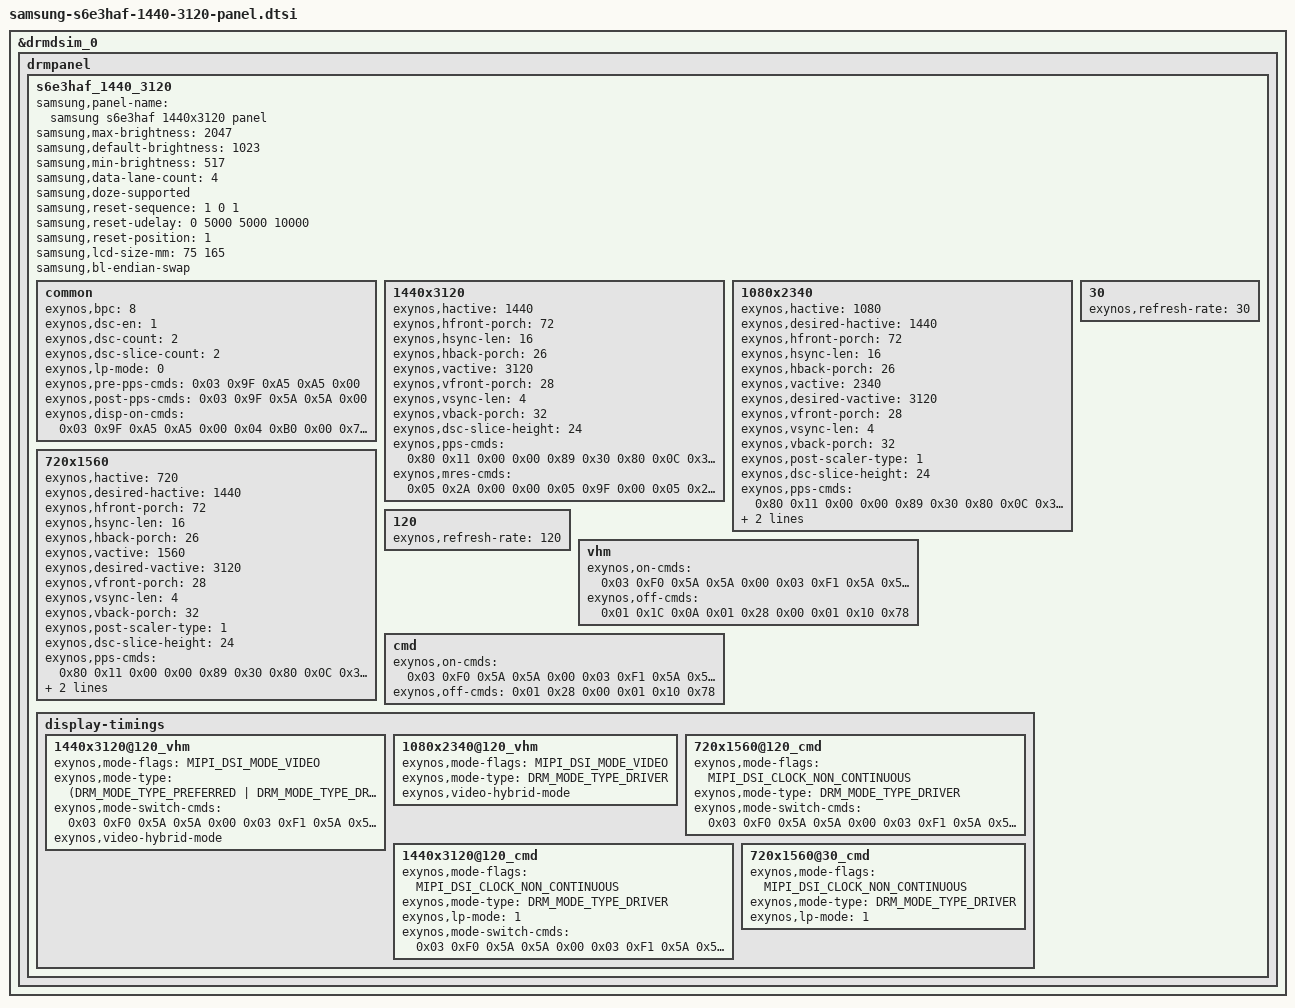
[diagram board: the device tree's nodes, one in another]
#include <dt-bindings/display/exynos-display.h>
#include <dt-bindings/display/exynos-mipi-display.h>

&drmdsim_0 {
	drmpanel {
		s6e3haf_1440_3120: s6e3haf_1440_3120 {
			samsung,panel-name = "samsung s6e3haf 1440x3120 panel";
			samsung,max-brightness = <2047>;
			samsung,default-brightness = <1023>;
			samsung,min-brightness = <517>;
			samsung,data-lane-count = <4>;
			samsung,doze-supported;

			samsung,reset-sequence = <1 0 1>;
			samsung,reset-udelay = <0 5000 5000 10000>;
			samsung,reset-position = <1>;

			samsung,lcd-size-mm = <75 165>; /* width x height */
			samsung,bl-endian-swap;

			/* common info & cmds */
			common {
				exynos,bpc = <8>;
				exynos,dsc-en = <1>;
				exynos,dsc-count = <2>;
				exynos,dsc-slice-count = <2>;

				exynos,lp-mode = <0>;

				exynos,pre-pps-cmds = <
					0x03 0x9F 0xA5 0xA5 0x00 /* PASSWD0 UNLOCK */
					>;
				exynos,post-pps-cmds = <
					0x03 0x9F 0x5A 0x5A 0x00 /* PASSWD0 LOCK */
					>;
				exynos,disp-on-cmds = <
					0x03 0x9F 0xA5 0xA5 0x00 /* PASSWD0 UNLOCK */
					/* set HCG_DIS(?) to 1 */
					0x04 0xB0 0x00 0x74 0x62 0x00
					0x02 0x62 0x01 0x00
					0x01 0x29 0x00
					0x03 0x9F 0x5A 0x5A 0x00 /* PASSWD0 LOCK */
					>;
			};
			/* resolution dependent info & cmds */
			1440x3120 {
				exynos,hactive = <1440>;
				exynos,hfront-porch = <72>; /* TODO: check (depends on tx mipi speed) */
				exynos,hsync-len = <16>; /* TODO: check (depends on tx mipi speed) */
				exynos,hback-porch = <26>; /* TODO: check (depends on tx mipi speed) */
				exynos,vactive = <3120>;
				exynos,vfront-porch = <28>;
				exynos,vsync-len = <4>;
				exynos,vback-porch = <32>;

				exynos,dsc-slice-height = <24>;

				exynos,pps-cmds = <
					0x80
					0x11 0x00 0x00 0x89 0x30 0x80 0x0C 0x30 0x05 0xA0
					0x00 0x18 0x02 0xD0 0x02 0xD0 0x02 0x00 0x02 0x68
					0x00 0x20 0x02 0xA1 0x00 0x0A 0x00 0x0C 0x04 0x2D
					0x03 0x2E 0x18 0x00 0x10 0xF0 0x03 0x0C 0x20 0x00
					0x06 0x0B 0x0B 0x33 0x0E 0x1C 0x2A 0x38 0x46 0x54
					0x62 0x69 0x70 0x77 0x79 0x7B 0x7D 0x7E 0x01 0x02
					0x01 0x00 0x09 0x40 0x09 0xBE 0x19 0xFC 0x19 0xFA
					0x19 0xF8 0x1A 0x38 0x1A 0x78 0x1A 0xB6 0x2A 0xF6
					0x2B 0x34 0x2B 0x74 0x3B 0x74 0x6B 0xF4 0x00 0x00
					0x00 0x00 0x00 0x00 0x00 0x00 0x00 0x00 0x00 0x00
					0x00 0x00 0x00 0x00 0x00 0x00 0x00 0x00 0x00 0x00
					0x00 0x00 0x00 0x00 0x00 0x00 0x00 0x00 0x00 0x00
					0x00 0x00 0x00 0x00 0x00 0x00 0x00 0x00
					0x00
					>;

				exynos,mres-cmds = <
					0x05 0x2A 0x00 0x00 0x05 0x9F 0x00
					0x05 0x2B 0x00 0x00 0x0C 0x2F 0x00
					>;
			};

			1080x2340 {
				exynos,hactive = <1080>;
				exynos,desired-hactive = <1440>;
				exynos,hfront-porch = <72>; /* TODO: check (depends on tx mipi speed) */
				exynos,hsync-len = <16>; /* TODO: check (depends on tx mipi speed) */
				exynos,hback-porch = <26>; /* TODO: check (depends on tx mipi speed) */
				exynos,vactive = <2340>;
				exynos,desired-vactive = <3120>;
				exynos,vfront-porch = <28>;
				exynos,vsync-len = <4>;
				exynos,vback-porch = <32>;
				exynos,post-scaler-type = <1>;

				exynos,dsc-slice-height = <24>;

				exynos,pps-cmds = <
					0x80
					0x11 0x00 0x00 0x89 0x30 0x80 0x0C 0x30 0x05 0xA0
					0x00 0x18 0x02 0xD0 0x02 0xD0 0x02 0x00 0x02 0x68
					0x00 0x20 0x02 0xA1 0x00 0x0A 0x00 0x0C 0x04 0x2D
					0x03 0x2E 0x18 0x00 0x10 0xF0 0x03 0x0C 0x20 0x00
					0x06 0x0B 0x0B 0x33 0x0E 0x1C 0x2A 0x38 0x46 0x54
					0x62 0x69 0x70 0x77 0x79 0x7B 0x7D 0x7E 0x01 0x02
					0x01 0x00 0x09 0x40 0x09 0xBE 0x19 0xFC 0x19 0xFA
					0x19 0xF8 0x1A 0x38 0x1A 0x78 0x1A 0xB6 0x2A 0xF6
					0x2B 0x34 0x2B 0x74 0x3B 0x74 0x6B 0xF4 0x00 0x00
					0x00 0x00 0x00 0x00 0x00 0x00 0x00 0x00 0x00 0x00
					0x00 0x00 0x00 0x00 0x00 0x00 0x00 0x00 0x00 0x00
					0x00 0x00 0x00 0x00 0x00 0x00 0x00 0x00 0x00 0x00
					0x00 0x00 0x00 0x00 0x00 0x00 0x00 0x00
					0x00
					>;

				exynos,mres-cmds = <
					0x05 0x2A 0x00 0x00 0x05 0x9F 0x00
					0x05 0x2B 0x00 0x00 0x0C 0x2F 0x00
					>;
			};

			720x1560 {
				exynos,hactive = <720>;
				exynos,desired-hactive = <1440>;
				exynos,hfront-porch = <72>; /* TODO: check (depends on tx mipi speed) */
				exynos,hsync-len = <16>; /* TODO: check (depends on tx mipi speed) */
				exynos,hback-porch = <26>; /* TODO: check (depends on tx mipi speed) */
				exynos,vactive = <1560>;
				exynos,desired-vactive = <3120>;
				exynos,vfront-porch = <28>;
				exynos,vsync-len = <4>;
				exynos,vback-porch = <32>;
				exynos,post-scaler-type = <1>;

				exynos,dsc-slice-height = <24>;

				exynos,pps-cmds = <
					0x80
					0x11 0x00 0x00 0x89 0x30 0x80 0x0C 0x30 0x05 0xA0
					0x00 0x18 0x02 0xD0 0x02 0xD0 0x02 0x00 0x02 0x68
					0x00 0x20 0x02 0xA1 0x00 0x0A 0x00 0x0C 0x04 0x2D
					0x03 0x2E 0x18 0x00 0x10 0xF0 0x03 0x0C 0x20 0x00
					0x06 0x0B 0x0B 0x33 0x0E 0x1C 0x2A 0x38 0x46 0x54
					0x62 0x69 0x70 0x77 0x79 0x7B 0x7D 0x7E 0x01 0x02
					0x01 0x00 0x09 0x40 0x09 0xBE 0x19 0xFC 0x19 0xFA
					0x19 0xF8 0x1A 0x38 0x1A 0x78 0x1A 0xB6 0x2A 0xF6
					0x2B 0x34 0x2B 0x74 0x3B 0x74 0x6B 0xF4 0x00 0x00
					0x00 0x00 0x00 0x00 0x00 0x00 0x00 0x00 0x00 0x00
					0x00 0x00 0x00 0x00 0x00 0x00 0x00 0x00 0x00 0x00
					0x00 0x00 0x00 0x00 0x00 0x00 0x00 0x00 0x00 0x00
					0x00 0x00 0x00 0x00 0x00 0x00 0x00 0x00
					0x00
					>;

				exynos,mres-cmds = <
					0x05 0x2A 0x00 0x00 0x05 0x9F 0x00
					0x05 0x2B 0x00 0x00 0x0C 0x2F 0x00
					>;
			};

			/* framerate dependent info & cmds */
			120 {
				exynos,refresh-rate = <120>;
			};

			30 {
				exynos,refresh-rate = <30>;
			};

			/* operation mode dependent info & cmds */
			vhm {
				exynos,on-cmds = <
					0x03 0xF0 0x5A 0x5A 0x00 /* PASSWD1 UNLOCK */
					0x03 0xF1 0x5A 0x5A 0x00 /* PASSWD2 UNLOCK */
					0x03 0xFC 0x5A 0x5A 0x00 /* PASSWD3? UNLOCK */

					/* don't make OTP Load operation forcingly after SLPOUT */
					0x02 0xD0 0x08 0x00

					0x04 0xB0 0x00 0x10 0xAB 0x00
					0x02 0xAB 0x74 0x00

					0x04 0xB0 0x00 0x74 0x62 0x00
					0x02 0x62 0x01 0x00

					/* Esync setting */
					0x7F
					0xF9 0xF1 0x00 0x00 0x00 0x00 0x02 0x20 0x00 0x80
					0x3F 0x3A 0x77 0x77 0x48 0x00 0x00 0x00 0x00 0x00
					0x00 0x00 0x80 0x01 0xAF 0x15 0x00 0x68 0x0A 0x00
					0x00 0x20 0x3F 0x01 0x50 0x52 0x00 0x00 0x00 0x00
					0x60 0x02 0x3F 0x1C 0x00 0x7D 0x0A 0x00 0x00 0x20
					0x3F 0x01 0xC0 0x3D 0x00 0x00 0x00 0x00 0x30 0x01
					0x67 0x11 0x00 0x7D 0x0A 0x00 0x00 0x20 0x3F 0x01
					0x10 0x52 0x00 0x00 0x00 0x00 0x40 0x03 0x5F 0x2B
					0x00 0x56 0x0A 0x00 0x00 0x20 0x3F 0x02 0xB0 0x52
					0x00 0x00 0x00 0x00 0x20 0x01 0x8C 0x1B 0x00 0x17
					0x09 0x00 0x00 0x17 0x3F 0x13 0xD0 0x52 0x00 0x00
					0x00 0x00 0x00 0x00 0x0C 0x00 0x00 0x00 0x00 0x00
					0x00 0x00 0x03 0x20 0x00 0x00 0x00
					0x00

					/* VRRCTL: Based on the VHM app. note v0.4 */
					0x04 0xB0 0x01 0x0D 0xBD 0x00
					0xF2
					0xBD 0x00 0x00 0x00 0x00 0x00 0x00 0x00 0x00 0x00
					0x00 0x01 0x00 0x00 0x00 0x01 0x00 0x00 0x00 0x77
					0x00 0x0B 0x00 0x00 0x00 0x77 0x00 0x00 0x00 0x00
					0x00 0x77 0x00 0x00 0x00 0x00 0x00 0x77 0x00 0x00
					0x00 0x00 0x00 0x77 0x00 0x0B 0x80 0x00 0x00 0x00
					0x00 0x00 0x00 0x00 0x00 0x00 0x00 0x00 0x00 0x00
					0x00 0x00 0x00 0x00 0x00 0x00 0x00 0x00 0x00 0x00
					0x00 0x00 0x00 0x00 0x00 0x00 0x00 0x00 0x00 0x00
					0x00 0x00 0x00 0x00 0x00 0x00 0x00 0x00 0x00 0x00
					0x00 0x00 0x00 0x00 0x00 0x00 0x00 0x00 0x00 0x00
					0x00 0x00 0x00 0x00 0x00 0x00 0x00 0x00 0x00 0x00
					0x00 0x00 0x40 0x00 0x00 0x00 0x00 0x00 0x00 0x00
					0x00 0x00 0x00 0x00 0x00 0x04 0x02 0x0A 0x01 0x16
					0x01 0xEE 0x00 0x00 0xEE 0x00 0xEE 0x00 0xEE 0x00
					0xEE 0x00 0x00 0x00 0x00 0x00 0x00 0x00 0x00 0x00
					0x00 0x00 0x00 0x00 0x00 0x00 0x00 0x00 0x00 0x00
					0x00 0x00 0x00 0x00 0x00 0x00 0x00 0x00 0x00 0x00
					0x00 0x00 0x00 0x00 0x00 0x00 0x00 0x00 0x00 0x00
					0x00 0x00 0x00 0x00 0x00 0x00 0x00 0x00 0x00 0x00
					0x00 0x00 0x00 0x00 0x00 0x00 0x00 0x00 0x00 0x00
					0x00 0x00 0x00 0x00 0x00 0x00 0x00 0x00 0x00 0x04
					0x02 0x0A 0x01 0x16 0x01 0xEE 0x00 0x00 0xEE 0x00
					0xEE 0x00 0xEE 0x00 0xEE 0x00 0x00 0x00 0x00 0x00
					0x00 0x00 0x00 0x20 0x00 0x00 0x00 0x00 0x04 0x00
					0x00 0x00
					0x00

					/* PANEL UPDATE */
					0x02 0xF7 0x0F 0x00

					/* sleep out: 120ms delay */
					0x01 0x11 0x78

					/* RW window setting: Based on the VHM app. note v0.4 */
					/* TE1_PSR_ST = 0x0C53 ((193th para << 8) + 194th para) */
					/* TE1_PSR_ED = 0x0637 ((195th para << 8) + 196th para) */
					0xEE
					0xB9 0x00 0x00 0x00 0x00 0x00 0x00 0x00 0x00 0x00
					0x0B 0xB8 0x00 0x00 0xC8 0x00 0x0B 0xB8 0x00 0x00
					0xC8 0x00 0x00 0x00 0x00 0x12 0x98 0x00 0x40 0x12
					0x68 0x00 0x00 0x00 0x00 0x00 0x00 0x00 0x00 0x00
					0x00 0x00 0x00 0x00 0x00 0x00 0x00 0x00 0x00 0x00
					0x00 0x00 0x00 0x00 0x00 0x00 0x00 0x00 0x00 0x00
					0x00 0x00 0x00 0x00 0x00 0x09 0x09 0x19 0x09 0x80
					0x82 0xB0 0x82 0x00 0x05 0x00 0x07 0x02 0x40 0x02
					0x40 0x02 0x40 0x02 0x40 0x00 0x00 0x00 0x00 0x00
					0x00 0x00 0x00 0x00 0x00 0x00 0x00 0x00 0x00 0x00
					0x00 0x00 0x00 0x00 0x00 0x00 0x00 0x00 0x00 0x00
					0x00 0x00 0x00 0x00 0x00 0x00 0x00 0x00 0x00 0x00
					0x00 0x00 0x00 0x00 0x00 0x00 0x00 0x00 0x00 0x00
					0x00 0x00 0x00 0x00 0x00 0x00 0x00 0x00 0x00 0x00
					0x00 0x00 0x00 0x00 0x00 0x00 0x00 0x00 0x00 0x00
					0x00 0x00 0x00 0x00 0x00 0x00 0x00 0x02 0x02 0x02
					0x02 0x02 0x02 0x02 0x02 0x00 0xFF 0x26 0x00 0x00
					0x10 0x00 0x00 0x00 0x80 0x03 0x00 0x00 0x00 0x80
					0x03 0x80 0x00 0x00 0x80 0x03 0x80 0x00 0x00 0x00
					0x03 0x00 0x00 0x0C 0x53 0x06 0x37 0x00 0x00 0x00
					0x04 0x00 0x00 0x00 0x00 0x00 0x0C 0x53 0x06 0x37
					0x00 0x00 0x00 0x04 0x00 0x00 0x00 0x00 0x00 0x8C
					0x60 0x80 0x10 0x00 0x00 0x00 0x00 0x00 0x00 0x00
					0x00 0x00 0x00 0x00 0x00 0x00 0x00 0x00
					0x00

					/* DISPCTL */
					0x03
					/* DM: 2nd para[3:2] (mode 1: video hybrid mode) */
					0xF2 0x01 0x04 0x00

					/* set_dsi_mode = 1 */
					0x02 0x71 0x01 0x00 /* 1st para (0: for cmd mode, 1: for vdo mode) */

					/* PANEL UPDATE */
					0x02 0xF7 0x0F 0x0A

					/* TE on */
					/* should be located after setting dispctl to video psr */
					0x02 0x35 0x00 0x00

					/*  brightness control */
					0x02 0x53 0x20 0x00
					0x03 0x51 0x03 0xFF 0x00
					>;

				exynos,off-cmds = <
					/*  STILL OFF */
					0x01 0x1C 0x0A

					0x01 0x28 0x00
					/* sleep in: 120ms delay */
					0x01 0x10 0x78
					>;
			};
			cmd {
				exynos,on-cmds = <
					0x03 0xF0 0x5A 0x5A 0x00 /* PASSWD1 UNLOCK */
					0x03 0xF1 0x5A 0x5A 0x00 /* PASSWD2 UNLOCK */
					0x03 0xFC 0x5A 0x5A 0x00 /* PASSWD3? UNLOCK */

					/* sleep out: 200ms delay */
					0x01 0x11 0xC8

					/* TE control */
					0x03 0xB9 0x00 0x00 0x00

					/* TE on */
					0x02 0x35 0x00 0x00

					/*  brightness control */
					0x02 0x53 0x20 0x00
					0x03 0x51 0x07 0xFF 0x00
					//0x02 0xD0 0x08 0x00
					0x02 0x83 0x00 0x00

					/* DISPCTL */
					0x03 0xF2 0x01 0x00 0x00 /* DM: 2nd para[3:2] (mode 0: command mode) */

					/* set_dsi_mode = 0 */
					0x02 0x71 0x00 0x00 /* 1st para (0: for cmd mode, 1: for vdo mode) */

					0x02 0xF7 0x0F 0x00 /* PANEL UPDATE */
					>;

				exynos,off-cmds = <
					0x01 0x28 0x00
					/* sleep in: 120ms delay */
					0x01 0x10 0x78
					>;
			};

			display-timings {
				/*
				* The exynos properties can be declared repeatedly in any node.
				* The properties of child nodes have a high priority
				* than properties of parent node.
				*/
				1440x3120@120_vhm {
					exynos,mode-flags = <MIPI_DSI_MODE_VIDEO>;
					exynos,mode-type = <(DRM_MODE_TYPE_PREFERRED |
							DRM_MODE_TYPE_DRIVER)>;

					exynos,mode-switch-cmds = <
						0x03 0xF0 0x5A 0x5A 0x00 /* PASSWD1 UNLOCK */
						0x03 0xF1 0x5A 0x5A 0x00 /* PASSWD2 UNLOCK */
						0x03 0xFC 0x5A 0x5A 0x00 /* PASSWD3? UNLOCK */

						0x04 0xB0 0x00 0x01 0xF2 0x00
						0x02 0xF2 0x04 0x00

						0x02 0x71 0x01 0x00
						0x02 0xF9 0xF1 0x00
						0x02 0xF7 0x0F 0x00
						0x02 0x35 0x00 0x00
						>;

					exynos,video-hybrid-mode;
				};
				1080x2340@120_vhm {
					exynos,mode-flags = <MIPI_DSI_MODE_VIDEO>;
					exynos,mode-type = <DRM_MODE_TYPE_DRIVER>;

					exynos,video-hybrid-mode;
				};
				720x1560@120_cmd {
					exynos,mode-flags = <MIPI_DSI_CLOCK_NON_CONTINUOUS>;
					exynos,mode-type = <DRM_MODE_TYPE_DRIVER>;

					exynos,mode-switch-cmds = <
						0x03 0xF0 0x5A 0x5A 0x00 /* PASSWD1 UNLOCK */
						0x03 0xF1 0x5A 0x5A 0x00 /* PASSWD2 UNLOCK */
						0x03 0xFC 0x5A 0x5A 0x00 /* PASSWD3? UNLOCK */

						/* TE control */
						0x04 0xB0 0x00 0x01 0xF2 0x00
						0x02 0xF2 0x00 0x00

						0x02 0x71 0x00 0x00
						0x02 0xF9 0x00 0x00
						0x02 0xF7 0x0F 0x00
						0x02 0x35 0x00 0x00
						>;
				};
				1440x3120@120_cmd {
					exynos,mode-flags = <MIPI_DSI_CLOCK_NON_CONTINUOUS>;
					exynos,mode-type = <DRM_MODE_TYPE_DRIVER>;
					exynos,lp-mode = <1>;

					exynos,mode-switch-cmds = <
						0x03 0xF0 0x5A 0x5A 0x00 /* PASSWD1 UNLOCK */
						0x03 0xF1 0x5A 0x5A 0x00 /* PASSWD2 UNLOCK */
						0x03 0xFC 0x5A 0x5A 0x00 /* PASSWD3? UNLOCK */

						/* TE control */
						0x04 0xB0 0x00 0x01 0xF2 0x00
						0x02 0xF2 0x00 0x00

						0x02 0x71 0x00 0x00
						0x02 0xF9 0x00 0x00
						0x02 0xF7 0x0F 0x00
						0x02 0x35 0x00 0x00
						>;
				};
				720x1560@30_cmd {
					exynos,mode-flags = <MIPI_DSI_CLOCK_NON_CONTINUOUS>;
					exynos,mode-type = <DRM_MODE_TYPE_DRIVER>;
					exynos,lp-mode = <1>;

					/* add switching & vref cmds */
				};
			};
		};
	};
};
